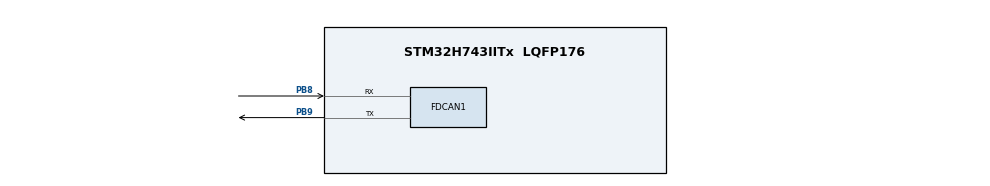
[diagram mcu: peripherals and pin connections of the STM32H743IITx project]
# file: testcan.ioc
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FDCAN1.CalculateBaudRateNominal=500000
FDCAN1.CalculateTimeBitNominal=2000
FDCAN1.CalculateTimeQuantumNominal=200.0
FDCAN1.NominalPrescaler=5
FDCAN1.NominalTimeSeg1=7
FDCAN1.NominalTimeSeg2=2
FDCAN1.RxFifo0ElmtsNbr=3
Mcu.Family=STM32H7
Mcu.Name=STM32H743IITx
Mcu.Package=LQFP176
NVIC.FDCAN1_IT0_IRQn=true\:0\:0\:false\:false\:true\:true\:true\:true
NVIC.FDCAN1_IT1_IRQn=true\:0\:0\:false\:false\:true\:true\:true\:true
NVIC.FDCAN_CAL_IRQn=true\:0\:0\:false\:false\:true\:true\:true\:true
NVIC.PriorityGroup=NVIC_PRIORITYGROUP_4
PB8.GPIO_Speed=GPIO_SPEED_FREQ_VERY_HIGH
PB8.Mode=FDCAN_Activate
PB8.Signal=FDCAN1_RX
PB9.GPIO_Speed=GPIO_SPEED_FREQ_VERY_HIGH
PB9.Mode=FDCAN_Activate
PB9.Signal=FDCAN1_TX
PH0-OSC_IN\ (PH0).Mode=HSE-External-Oscillator
PH0-OSC_IN\ (PH0).Signal=RCC_OSC_IN
PH1-OSC_OUT\ (PH1).Mode=HSE-External-Oscillator
PH1-OSC_OUT\ (PH1).Signal=RCC_OSC_OUT
ProjectManager.HeapSize=0x200
ProjectManager.StackSize=0x400
ProjectManager.TargetToolchain=STM32CubeIDE
RCC.ADCFreq_Value=129000000
RCC.APB1Freq_Value=64000000
RCC.APB2Freq_Value=64000000
RCC.APB3Freq_Value=64000000
RCC.APB4Freq_Value=64000000
RCC.CortexFreq_Value=64000000
RCC.DIVM1=4
RCC.DIVN1=10
RCC.DIVQ1=3
RCC.FDCANCLockSelection=RCC_FDCANCLKSOURCE_HSE
RCC.HCLKFreq_Value=64000000
RCC.PLLFRACN=0
RCC.SYSCLKFreq_VALUE=64000000
RCC.USBFreq_Value=53333333.333333336
VP_MEMORYMAP_VS_MEMORYMAP.Mode=CurAppReg
board=custom

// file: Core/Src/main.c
/* USER CODE BEGIN Header */
/**
  ******************************************************************************
  * @file           : main.c
  * @brief          : Main program body
  ******************************************************************************
  * @attention
  *
  * Copyright (c) 2025 STMicroelectronics.
  * All rights reserved.
  *
  * This software is licensed under terms that can be found in the LICENSE file
  * in the root directory of this software component.
  * If no LICENSE file comes with this software, it is provided AS-IS.
  *
  ******************************************************************************
  */
/* USER CODE END Header */
#include "main.h"
#include "fdcan.h"
#include "memorymap.h"
#include "gpio.h"

/* USER CODE BEGIN PV */
FDCAN_RxHeaderTypeDef RxHeader;
uint8_t RxData[8];
/* USER CODE END PV */

void SystemClock_Config(void);

int main(void)
{

  /* MCU Configuration--------------------------------------------------------*/

  /* Reset of all peripherals, Initializes the Flash interface and the Systick. */
  HAL_Init();

  /* Configure the system clock */
  SystemClock_Config();

  /* Initialize all configured peripherals */
  MX_GPIO_Init();
  MX_FDCAN1_Init();
  /* USER CODE BEGIN 2 */
  if (HAL_FDCAN_ConfigGlobalFilter(&hfdcan1,
                                     FDCAN_ACCEPT_IN_RX_FIFO0, // Standard ID -> Bierz
                                     FDCAN_ACCEPT_IN_RX_FIFO0, // Extended ID (VESC) -> Bierz
                                     FDCAN_REJECT,             // Remote frames -> Kosz
                                     FDCAN_REJECT) != HAL_OK)  // Remote frames -> Kosz
    {
        Error_Handler();
    }

    // KROK 2: Start FDCAN
    if (HAL_FDCAN_Start(&hfdcan1) != HAL_OK)
    {
        Error_Handler();
    }

    // KROK 3: Włącz powiadomienie (Przerwanie), że przyszła wiadomość
    if (HAL_FDCAN_ActivateNotification(&hfdcan1, FDCAN_IT_RX_FIFO0_NEW_MESSAGE, 0) != HAL_OK)
    {
        Error_Handler();
    }
    /* USER CODE END 2 */
  while (1)
  {

  }
}

void SystemClock_Config(void)
{
  RCC_OscInitTypeDef RCC_OscInitStruct = {0};
  RCC_ClkInitTypeDef RCC_ClkInitStruct = {0};

  /** Supply configuration update enable
  */
  HAL_PWREx_ConfigSupply(PWR_LDO_SUPPLY);

  /** Configure the main internal regulator output voltage
  */
  __HAL_PWR_VOLTAGESCALING_CONFIG(PWR_REGULATOR_VOLTAGE_SCALE3);

  while(!__HAL_PWR_GET_FLAG(PWR_FLAG_VOSRDY)) {}

  /** Initializes the RCC Oscillators according to the specified parameters
  * in the RCC_OscInitTypeDef structure.
  */
  RCC_OscInitStruct.OscillatorType = RCC_OSCILLATORTYPE_HSI|RCC_OSCILLATORTYPE_HSE;
  RCC_OscInitStruct.HSEState = RCC_HSE_ON;
  RCC_OscInitStruct.HSIState = RCC_HSI_DIV1;
  RCC_OscInitStruct.HSICalibrationValue = RCC_HSICALIBRATION_DEFAULT;
  RCC_OscInitStruct.PLL.PLLState = RCC_PLL_NONE;
  if (HAL_RCC_OscConfig(&RCC_OscInitStruct) != HAL_OK)
  {
    Error_Handler();
  }

  /** Initializes the CPU, AHB and APB buses clocks
  */
  RCC_ClkInitStruct.ClockType = RCC_CLOCKTYPE_HCLK|RCC_CLOCKTYPE_SYSCLK
                              |RCC_CLOCKTYPE_PCLK1|RCC_CLOCKTYPE_PCLK2
                              |RCC_CLOCKTYPE_D3PCLK1|RCC_CLOCKTYPE_D1PCLK1;
  RCC_ClkInitStruct.SYSCLKSource = RCC_SYSCLKSOURCE_HSI;
  RCC_ClkInitStruct.SYSCLKDivider = RCC_SYSCLK_DIV1;
  RCC_ClkInitStruct.AHBCLKDivider = RCC_HCLK_DIV1;
  RCC_ClkInitStruct.APB3CLKDivider = RCC_APB3_DIV1;
  RCC_ClkInitStruct.APB1CLKDivider = RCC_APB1_DIV1;
  RCC_ClkInitStruct.APB2CLKDivider = RCC_APB2_DIV1;
  RCC_ClkInitStruct.APB4CLKDivider = RCC_APB4_DIV1;

  if (HAL_RCC_ClockConfig(&RCC_ClkInitStruct, FLASH_LATENCY_1) != HAL_OK)
  {
    Error_Handler();
  }
}

/* USER CODE BEGIN 4 */
void HAL_FDCAN_RxFifo0Callback(FDCAN_HandleTypeDef *hfdcan, uint32_t RxFifo0ITs)
{
    // Czy to powiadomienie o nowej wiadomości?
    if ((RxFifo0ITs & FDCAN_IT_RX_FIFO0_NEW_MESSAGE) != 0)
    {
        // Pobierz wiadomość do RxData
        if (HAL_FDCAN_GetRxMessage(hfdcan, FDCAN_RX_FIFO0, &RxHeader, RxData) == HAL_OK)
        {
            // ---> TU POSTAW BREAKPOINT <---
            // Jeśli tu wejdzie, w RxData[0]...RxData[7] masz dane z VESC.
            // W RxHeader.Identifier masz ID (np. kto to wysłał).
            // Kod nie sprawdza ID, po prostu bierze dane.
        }

        // Ponów nasłuchiwanie (niektóre wersje bibliotek tego wymagają)
        HAL_FDCAN_ActivateNotification(hfdcan, FDCAN_IT_RX_FIFO0_NEW_MESSAGE, 0);
    }
}

/* USER CODE END 4 */

void Error_Handler(void)
{
  __disable_irq();
  while (1)
  {
  }
}
